# AE101F4071542LH_CM55_HE_View register map
Vendor: Alif Semiconductor; Series: E1; File version: 1.0
CPU: CM55 r1p0, selectable endian, MPU, FPU, double-precision FPU, DSP, VTOR, 8 interrupt priority bits, 1 SAU regions
Registers are 32-bit, read-write, reset 0x0 unless marked. A register's access mark holds for its fields unless they carry their own. Offsets are from the block's base; [hi:lo] are bit positions; lines under a group give offsets from that group; {n}, {i} and the like mark numbered series; 'fields as' and 'values as' point back to an identical list.

## PINMUX
Base 0x1A603000
{0x0+0x20*i} PINMUX_CFG[{i}] (i=0..14) group
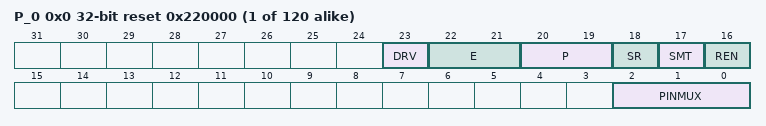
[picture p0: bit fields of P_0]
  {0x0+4j} P_{j} reset 0x220000 (j=0..7) — Control Register for Port n, Pin {j}
    [23] DRV — Driver type
      0=Push-pull; 1=Open drain
    [22:21] E — Output drive strength NOTE: Reset value is 0x3 (12 mA) for registers P4_4, P4_5, P4_6, P4_7
      0=2 mA; 1=4 mA; 2=8 mA; 3=12 mA
    [20:19] P — Driver disabled state control
      0=High-Z; 1=Pull-up; 2=Pull-down; 3=Bus keeper
    [18] SR — Slew rate
      0=Slow; 1=Fast
    [17] SMT — Schmitt trigger (hysteresis) enable
      0=No hysteresis; 1=Hysteresis enabled
    [16] REN — Receiver enable NOTE: Reset value is 0x1 for registers P4_4, P4_5, P4_6, P4_7, P8_5, P8_6, P8_7, P9_0
      0=Receiver disabled, pin reads return 0; 1=Receiver enabled
    [2:0] PINMUX — Pin multiplexing control field 0x1-0xN: Selects other peripherals as shown in table Pin Function Multiplexing of the device series-specific Datasheet. Un-mapped: Select GPIOn_{j} NOTE: Reset value is 0x1 for registers P4_4, P4_5, P4_6, P4_7, P8_5, P8_6, P8_7, P9_0
      0=Selects GPIOn_{j} signal from GPIOn peripheral

## AON
Base 0x1A604000
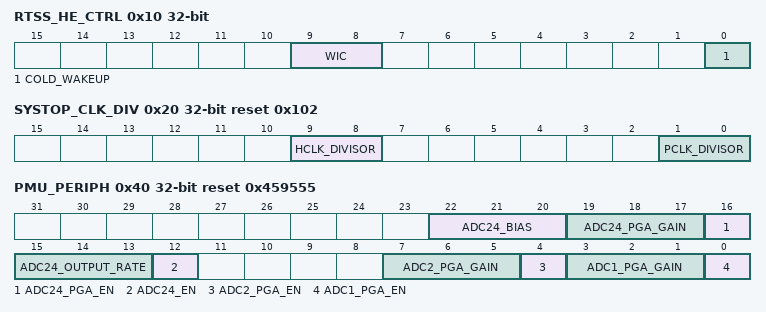
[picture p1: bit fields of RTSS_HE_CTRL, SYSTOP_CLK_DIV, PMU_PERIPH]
0x10 RTSS_HE_CTRL — M55-HE Control Register
  [9:8] WIC — Control bits mapped to WICCONTROL[1:0] configuration signal of M55-HE. Bit [9] is mapped to WICCONTROL[1]. Bit [8] is mapped to WICCONTROL[0]. For more information, refer to Arm(R) Cortex(R)-M55 Processor Technical Reference Manual.
  [0] COLD_WAKEUP — Set this bit to wake up M55-HE power domain during cold boot or waking-up from stop mode, clear it once power-on sequence is complete to enable dynamic power transitions of M55-HE.
0x14 RTSS_HE_RESET reset 0x1 — M55-HE Reset Status Register
  [5:0] RESETSYNDROME wo write-1-clears — Reset status set by hardware and cleared by software
    0=The last reset of M55-HE was caused by POR or Secure Enclave initiated reset; 1=The last reset of M55-HE was caused by NSRST pin being asserted; 4=The last reset of M55-HE was caused by a reset request to the power domain
0x1C RTSS_HE_LPUART_CKEN — LPUART Clock Enable Register
  [0] UART_CKEN — Enable clock for LPUART
    0=Disable clock; 1=Enable clock
0x20 SYSTOP_CLK_DIV reset 0x102 — System Bus Clock Divider Control Register
  [9:8] HCLK_DIVISOR — SYST_HCLK clock divisor
    0=Divide by 1; 1=Divide by 2; 2=Divide by 4; 3=Divide by 4
  [1:0] PCLK_DIVISOR — SYST_PCLK clock divisor
    0=Divide by 1; 1=Divide by 2; 2=Divide by 4; 3=Divide by 4
0x30 MISC_REG1 — HFXO Divider Control Register
  [16:13] CLKDIV — HFXO divisor
    0=Divide by 1; 1=Divide by 2; 2=Divide by 4; 3=Divide by 8; 4=Divide by 16; 5=Divide by 32; 6=Divide by 64; 7=Divide by 128; 8=Divide by 1; 9=Divide by 2; 10=Divide by 4; 11=Divide by 16; 12=Divide by 64; 13=Divide by 128; 14=Divide by 256; 15=Divide by 1024
0x40 PMU_PERIPH reset 0x459555 — ADC Control Register
  [22:20] ADC24_BIAS — ADC24 bias control
  [19:17] ADC24_PGA_GAIN — ADC24 PGA gain value
    0=0 dB; 1=6 dB; 2=12 dB; 3=18 dB; 4=24 dB; 5=30 dB; 6=36 dB; 7=42 dB
  [16] ADC24_PGA_EN — ADC24 PGA enable
    0=Disabled; 1=Enabled
  [15:13] ADC24_OUTPUT_RATE — ADC24 output rate select
  [12] ADC24_EN — ADC24 enable
    0=Disabled; 1=Enabled
  [7:5] ADC2_PGA_GAIN — ADC121 PGA gain value select
    values as ADC24_PGA_GAIN
  [4] ADC2_PGA_EN — ADC121 PGA enable Note: ADC121 must be put into differential mode when PGA is enabled
    0=Disabled; 1=Enabled
  [3:1] ADC1_PGA_GAIN — ADC120 PGA gain value select
    values as ADC24_PGA_GAIN
  [0] ADC1_PGA_EN — ADC120 PGA enable Note: ADC120 must be put into differential mode when PGA is enabled
    0=Disabled; 1=Enabled
